# PCIE1_CORE_DBN_CFG_PCIE_CORE register map
Vendor: Texas Instruments
Registers are 32-bit, read-write, reset 0x0 unless marked. A register's access mark holds for its fields unless they carry their own. Offsets are as the file gives them; [hi:lo] are bit positions; {n}, {i} and the like mark numbered series; 'fields as' and 'values as' point back to an identical list.

## PCIE1_CORE_DBN_CFG_PCIE_CORE (part 7 of 7)
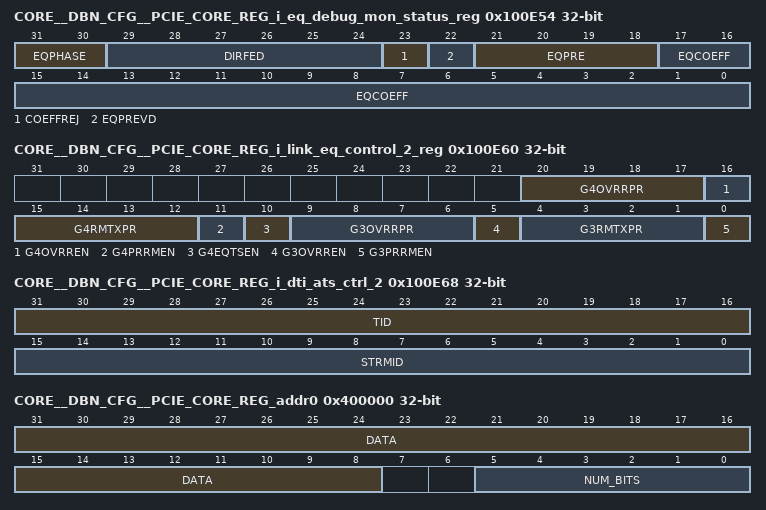
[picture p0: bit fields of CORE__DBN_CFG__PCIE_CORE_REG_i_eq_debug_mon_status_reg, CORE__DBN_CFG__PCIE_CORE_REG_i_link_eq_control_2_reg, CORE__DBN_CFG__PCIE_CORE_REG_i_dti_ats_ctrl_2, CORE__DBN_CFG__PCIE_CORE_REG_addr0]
0x100E54 CORE__DBN_CFG__PCIE_CORE_REG_i_eq_debug_mon_status_reg ro — All the Dynamic Equalization information is captured in this Register.This is implemented using a synchronous FIFO which stores all the captured events as sepereate 32 bit entries.The define den_db_EQ_DEBUG_FIFO_NUM_ENTRIES in defines.h controls the number of entries of the FIFO.Every read increments the read pointer and the client must store the data read.The FIFO can be cleared using the 'Clear all Capture bit in the EQ Debug Monitor Control Register.
  [31:30] EQPHASE — Equalization Phase during Capture 00 : Phase 0, 01 : Phase 1, 10 : Phase 2, 11 : Phase 3
  [29:24] DIRFED — EP Ph2/RC Ph3: Stores Direction Change Feedback or Preset feedback Transmitted to Remote Device. Bit-22, EQPREVD, indicates if this is a Preset feedback or Direction Change Feedback. EP Ph3/RC Ph2: Reserved
  [23] COEFFREJ — Phase0: Set to '1' if an unsupported preset is received in Phase0. Phase1: Set to '0' since no reject in phase1. EP Ph2/RC Ph3: Indicates Reject by the Remote end device. This bit indicates that the current Coefficient or Preset was rejected by the remote end device. EP Ph3/RC Ph2: Indicates that Controller Rejected the received settings to Remote Device in the TX TS1/TS2. This Reject indicates the current Coefficients or Preset received from Remote Device are rejected
  [22] EQPREVD — 1: Preset Valid, Indicates [21:18] is valid. Phase0: Set to '1' to indicate that the intial Local Preset is Valid. Phase1: Set to '1' to indicate that the advertised Remote Preset is Valid. EP Ph2/RC Ph3: Set to 1 if controller provide preset feedback and to 0 for coefficient feedback. EP Ph3/RC Ph2: Reflects the use preset bit received from the remote end.
  [21:18] EQPRE — Phase0: Stores Initial Local TX Preset received in Phase0. Phase1: Stores Initial Remote Preset advertised in Phase1. EP Ph2/RC Phase3: Stores Current Preset of the Remote Device. EP Ph3/RC Phase2: Stores Preset Received from Remote Device.
  [17:0] EQCOEFF — Phase0: Stores Initial Local TX Coefficients mapped from Initial Preset. Phase1: Stores Initial Remote Coefficients advertised in Phase1. [Cp, LF, FS] , EP Ph2/RC Phase3: Stores Current Coefficients of the Remote Device. EP Ph3/RC Phase2: Stores Coefficients Received from Remote Device.
0x100E5C CORE__DBN_CFG__PCIE_CORE_REG_i_axi_feature_reg reset 0x2 — This register is for the control of AXI Features
  [1] SLVERRCTRL — This bit if set to 1, AXI Slave masks the SLVERR response to be given in case of UR or CRS completion for configuration requests. If this bit is set to 0,UR and CRS completions from the link causes SLVERR at AXI.
0x100E60 CORE__DBN_CFG__PCIE_CORE_REG_i_link_eq_control_2_reg — This register implements fields to control and override Link Equalization.
  [20:17] G4OVRRPR — This is a debug register field. Can be used in both EP and RP Mode. When enabled using bit-16, this Tx Preset will be applied to the local Transmitter throughout Gen4 regardless of Gen4 Equalization.
  [16] G4OVRREN — This is a debug bit. Can be used in both EP and RP Mode. If enabled, the Controller locally applies the Gen4 Local Override Tx Preset to the Local Transmitter throughout Gen4. The Controller performs the Override Preset to Coefficient mapping and then drives on PIPE_TX_DEEMPHASIS signal on the PIPE Interface.
  [15:12] G4RMTXPR — Used only in EP Mode. If enabled, this Tx Preset will be transmitted in 8G EQ TS2s during Gen3 to Gen4 Speed Change negotiation. Also, If enabled, this Tx Preset will be transmitted in TS1s in the first iteration of Gen4 Equalization Phase2. Note: If the Remote end device advertised the same preset at start of Equalization Phase2, then this Preset will be skipped.
  [11] G4PRRMEN — Used only in EP Mode. This bit enables the Controller, to feedback a Tx Preset for the Remote end Transmitter in the first iteration of Link Equalization Phase2 at Gen4 speed. The Gen4 Tx Preset that is used for feedback is programmable in bits [15:12] of this register.
  [10] G4EQTSEN — Used only in EP Mode. During Gen3 to Gen4 Speed Change negotiation, this bit enables the Controller in EP Mode to transmit 8G EQ TS2 in Recovery.Rcvr.Cfg state instead of standard TS2 as defined in PCIe specification. The Tx Preset that will be used in the 8GT EQ TS2 is programmable in bits [15:12] of this register.
  [9:6] G3OVRRPR — This is a debug register field. Can be used in both EP and RP Mode. When enabled using bit-5, this Tx Preset will be applied to the local Transmitter throughout Gen3 regardless of Gen3 Equalization.
  [5] G3OVRREN — This is a debug bit. Can be used in both EP and RP Mode. If enabled, the Controller locally applies the Gen3 Local Override Tx Preset to the Local Transmitter throughout Gen3. The Controller performs the Override Preset to Coefficient mapping and then drives on PIPE_TX_DEEMPHASIS signal on the PIPE Interface.
  [4:1] G3RMTXPR — Used only in EP Mode. When enabled using bit-0, this Tx Preset will be transmitted in TS1s for the Remote end Transmitter in the first iteration of Gen3 Equalization Phase2. Reserved for RP Mode.
  [0] G3PRRMEN — Used only in EP Mode. This bit enables the Controller, to feedback a Tx Preset for the Remote end Transmitter in the first iteration of Link Equalization Phase2 at Gen3 speed. The Gen3 Tx Preset that is used for feedback is programmable in bits [4:1] of this register. Reserved for RP Mode.
0x100E64 CORE__DBN_CFG__PCIE_CORE_REG_i_core_feature_reg — This register is for the control of Core Features
  [1] APBCTRL — When set the Core will return SLVERR on the APB bus for Read or Writes to Configuration or Local Management registers
0x100E68 CORE__DBN_CFG__PCIE_CORE_REG_i_dti_ats_ctrl_2 — This register is for the control of DTI ATS Master
  [31:16] TID — This 16 bit value is used to drive the 16 bit TID_DTI_DN pin of the DTI Master
  [15:0] STRMID — This 16 bit value is used to filter [upper 16 bits of the SID is matched with this value] the DTI_ATS_INV_REQ and DTI_ATS_PAGE_RESP messages sent[broadcast] from the SMMU in case of multiple DTI Masters. This value used for the upper 16 bits of the SID in DTI_ATS_TRANS_REQ and DTI_ATS_PAGE_REQ
0x100E88 CORE__DBN_CFG__PCIE_CORE_REG_i_rx_invert_polarity_reg ro — This register shows the polarity inversion status of each lane
  [3:0] RIPR — shows the polarity inversion status of each lane
0x400000 CORE__DBN_CFG__PCIE_CORE_REG_addr0 access per field — Provides bits 31:8 of the PCIe address and the number of AXI address bits passed through
  [31:8] DATA rw — Bits [31:8] of PCIe Address Register for region N
  [5:0] NUM_BITS rw — Number_bits + 1 bits are passed through from AXI address to the PCIe address
0x400004 CORE__DBN_CFG__PCIE_CORE_REG_addr1 — Provides bits 63:32 of the PCIe address
  [31:0] DATA — Bits [63:32] of PCIe Address Register for region N
0x400008 CORE__DBN_CFG__PCIE_CORE_REG_desc0 — Provides bits 31:0 of the Outbound PCIe Descriptor
  [31:0] DATA — Lowest 32-bits of PCIe Descriptor Register for region N
0x40000C CORE__DBN_CFG__PCIE_CORE_REG_desc1 — Provides bits 63:32 of the PCIe Descriptor
  [31:0] DATA — Lower middle 32-bits of PCIe Descriptor Register for region N
0x400014 CORE__DBN_CFG__PCIE_CORE_REG_desc3 — Provides PASID Value and The present bit
  [22:0] DATA — {Execute Permission Supported, Privileged Mode Supported, PASID Value, PASID present bit}
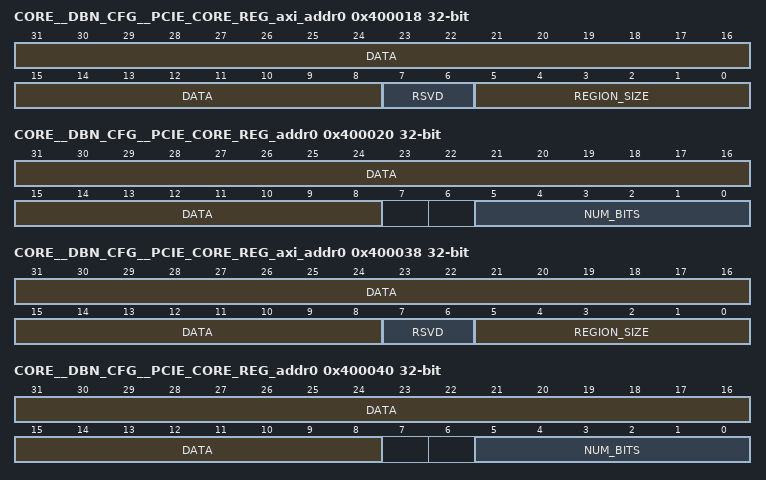
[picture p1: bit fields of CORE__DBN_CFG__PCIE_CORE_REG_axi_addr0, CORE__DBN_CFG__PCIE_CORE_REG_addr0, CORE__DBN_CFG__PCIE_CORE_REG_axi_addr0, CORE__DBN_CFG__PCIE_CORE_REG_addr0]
0x400018 CORE__DBN_CFG__PCIE_CORE_REG_axi_addr0 — holds the base address [31:8] of this region. Lower [5:0] is used for region size programmability
  [31:8] DATA — Bits [31:8] of Outbound AXI Region Base Address Register used to decode the region
  [7:6] RSVD — These needs to be forced to 0
  [5:0] REGION_SIZE — the value programmed in this field + 1 gives the region size
0x40001C CORE__DBN_CFG__PCIE_CORE_REG_axi_addr1 — holds the base address [63:32] of this region.
  [31:0] DATA — Bits [63:32] of AXI outbound Base Address Register used to decode the region
0x400020 CORE__DBN_CFG__PCIE_CORE_REG_addr0 access per field — Provides bits 31:8 of the PCIe address and the number of AXI address bits passed through
  fields as CORE__DBN_CFG__PCIE_CORE_REG_addr0
0x400024 CORE__DBN_CFG__PCIE_CORE_REG_addr1 — Provides bits 63:32 of the PCIe address
  [31:0] DATA — Bits [63:32] of PCIe Address Register for region N
0x400028 CORE__DBN_CFG__PCIE_CORE_REG_desc0 — Provides bits 31:0 of the Outbound PCIe Descriptor
  fields as CORE__DBN_CFG__PCIE_CORE_REG_desc0
0x40002C CORE__DBN_CFG__PCIE_CORE_REG_desc1 — Provides bits 63:32 of the PCIe Descriptor
  fields as CORE__DBN_CFG__PCIE_CORE_REG_desc1
0x400034 CORE__DBN_CFG__PCIE_CORE_REG_desc3 — Provides PASID Value and The present bit
  fields as CORE__DBN_CFG__PCIE_CORE_REG_desc3
0x400038 CORE__DBN_CFG__PCIE_CORE_REG_axi_addr0 — holds the base address [31:8] of this region. Lower [5:0] is used for region size programmability
  fields as CORE__DBN_CFG__PCIE_CORE_REG_axi_addr0
0x40003C CORE__DBN_CFG__PCIE_CORE_REG_axi_addr1 — holds the base address [63:32] of this region.
  fields as CORE__DBN_CFG__PCIE_CORE_REG_axi_addr1
0x400040 CORE__DBN_CFG__PCIE_CORE_REG_addr0 access per field — Provides bits 31:8 of the PCIe address and the number of AXI address bits passed through
  fields as CORE__DBN_CFG__PCIE_CORE_REG_addr0
0x400044 CORE__DBN_CFG__PCIE_CORE_REG_addr1 — Provides bits 63:32 of the PCIe address
  [31:0] DATA — Bits [63:32] of PCIe Address Register for region N
0x400048 CORE__DBN_CFG__PCIE_CORE_REG_desc0 — Provides bits 31:0 of the Outbound PCIe Descriptor
  fields as CORE__DBN_CFG__PCIE_CORE_REG_desc0
0x40004C CORE__DBN_CFG__PCIE_CORE_REG_desc1 — Provides bits 63:32 of the PCIe Descriptor
  fields as CORE__DBN_CFG__PCIE_CORE_REG_desc1
0x400054 CORE__DBN_CFG__PCIE_CORE_REG_desc3 — Provides PASID Value and The present bit
  fields as CORE__DBN_CFG__PCIE_CORE_REG_desc3
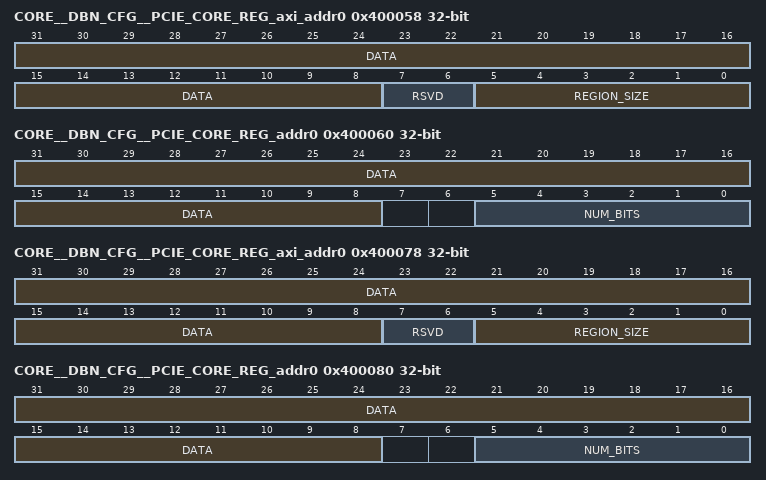
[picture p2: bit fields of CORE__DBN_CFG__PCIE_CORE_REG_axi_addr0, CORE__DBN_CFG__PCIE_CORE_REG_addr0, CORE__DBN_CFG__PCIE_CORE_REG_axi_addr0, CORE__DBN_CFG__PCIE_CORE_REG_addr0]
0x400058 CORE__DBN_CFG__PCIE_CORE_REG_axi_addr0 — holds the base address [31:8] of this region. Lower [5:0] is used for region size programmability
  fields as CORE__DBN_CFG__PCIE_CORE_REG_axi_addr0
0x40005C CORE__DBN_CFG__PCIE_CORE_REG_axi_addr1 — holds the base address [63:32] of this region.
  fields as CORE__DBN_CFG__PCIE_CORE_REG_axi_addr1
0x400060 CORE__DBN_CFG__PCIE_CORE_REG_addr0 access per field — Provides bits 31:8 of the PCIe address and the number of AXI address bits passed through
  fields as CORE__DBN_CFG__PCIE_CORE_REG_addr0
0x400064 CORE__DBN_CFG__PCIE_CORE_REG_addr1 — Provides bits 63:32 of the PCIe address
  [31:0] DATA — Bits [63:32] of PCIe Address Register for region N
0x400068 CORE__DBN_CFG__PCIE_CORE_REG_desc0 — Provides bits 31:0 of the Outbound PCIe Descriptor
  fields as CORE__DBN_CFG__PCIE_CORE_REG_desc0
0x40006C CORE__DBN_CFG__PCIE_CORE_REG_desc1 — Provides bits 63:32 of the PCIe Descriptor
  fields as CORE__DBN_CFG__PCIE_CORE_REG_desc1
0x400074 CORE__DBN_CFG__PCIE_CORE_REG_desc3 — Provides PASID Value and The present bit
  fields as CORE__DBN_CFG__PCIE_CORE_REG_desc3
0x400078 CORE__DBN_CFG__PCIE_CORE_REG_axi_addr0 — holds the base address [31:8] of this region. Lower [5:0] is used for region size programmability
  fields as CORE__DBN_CFG__PCIE_CORE_REG_axi_addr0
0x40007C CORE__DBN_CFG__PCIE_CORE_REG_axi_addr1 — holds the base address [63:32] of this region.
  fields as CORE__DBN_CFG__PCIE_CORE_REG_axi_addr1
0x400080 CORE__DBN_CFG__PCIE_CORE_REG_addr0 access per field — Provides bits 31:8 of the PCIe address and the number of AXI address bits passed through
  fields as CORE__DBN_CFG__PCIE_CORE_REG_addr0
0x400084 CORE__DBN_CFG__PCIE_CORE_REG_addr1 — Provides bits 63:32 of the PCIe address
  [31:0] DATA — Bits [63:32] of PCIe Address Register for region N
0x400088 CORE__DBN_CFG__PCIE_CORE_REG_desc0 — Provides bits 31:0 of the Outbound PCIe Descriptor
  fields as CORE__DBN_CFG__PCIE_CORE_REG_desc0
0x40008C CORE__DBN_CFG__PCIE_CORE_REG_desc1 — Provides bits 63:32 of the PCIe Descriptor
  fields as CORE__DBN_CFG__PCIE_CORE_REG_desc1
0x400094 CORE__DBN_CFG__PCIE_CORE_REG_desc3 — Provides PASID Value and The present bit
  fields as CORE__DBN_CFG__PCIE_CORE_REG_desc3
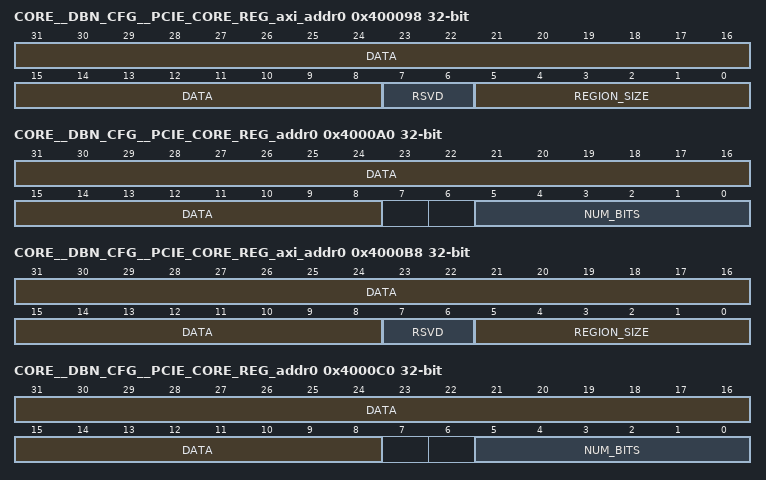
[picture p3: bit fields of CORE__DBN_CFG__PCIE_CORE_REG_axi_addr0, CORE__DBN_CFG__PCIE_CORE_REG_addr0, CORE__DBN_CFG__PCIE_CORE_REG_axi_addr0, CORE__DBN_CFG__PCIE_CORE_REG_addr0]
0x400098 CORE__DBN_CFG__PCIE_CORE_REG_axi_addr0 — holds the base address [31:8] of this region. Lower [5:0] is used for region size programmability
  fields as CORE__DBN_CFG__PCIE_CORE_REG_axi_addr0
0x40009C CORE__DBN_CFG__PCIE_CORE_REG_axi_addr1 — holds the base address [63:32] of this region.
  fields as CORE__DBN_CFG__PCIE_CORE_REG_axi_addr1
0x4000A0 CORE__DBN_CFG__PCIE_CORE_REG_addr0 access per field — Provides bits 31:8 of the PCIe address and the number of AXI address bits passed through
  fields as CORE__DBN_CFG__PCIE_CORE_REG_addr0
0x4000A4 CORE__DBN_CFG__PCIE_CORE_REG_addr1 — Provides bits 63:32 of the PCIe address
  [31:0] DATA — Bits [63:32] of PCIe Address Register for region N
0x4000A8 CORE__DBN_CFG__PCIE_CORE_REG_desc0 — Provides bits 31:0 of the Outbound PCIe Descriptor
  fields as CORE__DBN_CFG__PCIE_CORE_REG_desc0
0x4000AC CORE__DBN_CFG__PCIE_CORE_REG_desc1 — Provides bits 63:32 of the PCIe Descriptor
  fields as CORE__DBN_CFG__PCIE_CORE_REG_desc1
0x4000B4 CORE__DBN_CFG__PCIE_CORE_REG_desc3 — Provides PASID Value and The present bit
  fields as CORE__DBN_CFG__PCIE_CORE_REG_desc3
0x4000B8 CORE__DBN_CFG__PCIE_CORE_REG_axi_addr0 — holds the base address [31:8] of this region. Lower [5:0] is used for region size programmability
  fields as CORE__DBN_CFG__PCIE_CORE_REG_axi_addr0
0x4000BC CORE__DBN_CFG__PCIE_CORE_REG_axi_addr1 — holds the base address [63:32] of this region.
  fields as CORE__DBN_CFG__PCIE_CORE_REG_axi_addr1
0x4000C0 CORE__DBN_CFG__PCIE_CORE_REG_addr0 access per field — Provides bits 31:8 of the PCIe address and the number of AXI address bits passed through
  fields as CORE__DBN_CFG__PCIE_CORE_REG_addr0
0x4000C4 CORE__DBN_CFG__PCIE_CORE_REG_addr1 — Provides bits 63:32 of the PCIe address
  [31:0] DATA — Bits [63:32] of PCIe Address Register for region N
0x4000C8 CORE__DBN_CFG__PCIE_CORE_REG_desc0 — Provides bits 31:0 of the Outbound PCIe Descriptor
  fields as CORE__DBN_CFG__PCIE_CORE_REG_desc0
0x4000CC CORE__DBN_CFG__PCIE_CORE_REG_desc1 — Provides bits 63:32 of the PCIe Descriptor
  fields as CORE__DBN_CFG__PCIE_CORE_REG_desc1
0x4000D4 CORE__DBN_CFG__PCIE_CORE_REG_desc3 — Provides PASID Value and The present bit
  fields as CORE__DBN_CFG__PCIE_CORE_REG_desc3
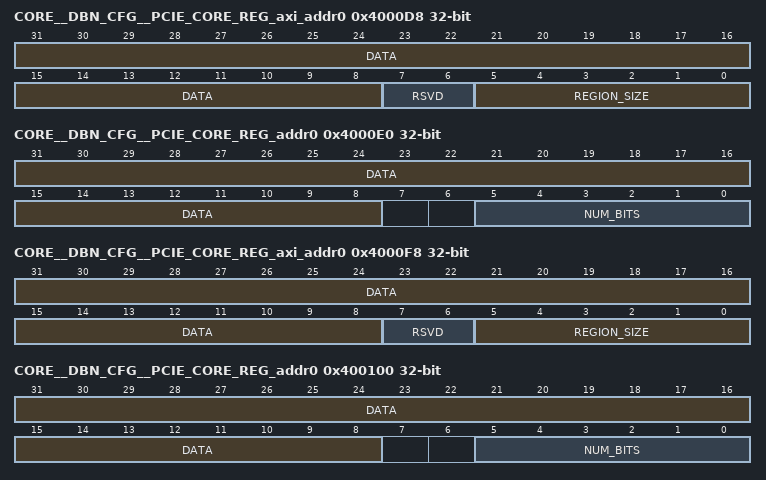
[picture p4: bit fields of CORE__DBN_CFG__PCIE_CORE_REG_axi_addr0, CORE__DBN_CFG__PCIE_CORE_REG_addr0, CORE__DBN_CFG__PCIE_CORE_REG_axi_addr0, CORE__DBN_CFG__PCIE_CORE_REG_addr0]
0x4000D8 CORE__DBN_CFG__PCIE_CORE_REG_axi_addr0 — holds the base address [31:8] of this region. Lower [5:0] is used for region size programmability
  fields as CORE__DBN_CFG__PCIE_CORE_REG_axi_addr0
0x4000DC CORE__DBN_CFG__PCIE_CORE_REG_axi_addr1 — holds the base address [63:32] of this region.
  fields as CORE__DBN_CFG__PCIE_CORE_REG_axi_addr1
0x4000E0 CORE__DBN_CFG__PCIE_CORE_REG_addr0 access per field — Provides bits 31:8 of the PCIe address and the number of AXI address bits passed through
  fields as CORE__DBN_CFG__PCIE_CORE_REG_addr0
0x4000E4 CORE__DBN_CFG__PCIE_CORE_REG_addr1 — Provides bits 63:32 of the PCIe address
  [31:0] DATA — Bits [63:32] of PCIe Address Register for region N
0x4000E8 CORE__DBN_CFG__PCIE_CORE_REG_desc0 — Provides bits 31:0 of the Outbound PCIe Descriptor
  fields as CORE__DBN_CFG__PCIE_CORE_REG_desc0
0x4000EC CORE__DBN_CFG__PCIE_CORE_REG_desc1 — Provides bits 63:32 of the PCIe Descriptor
  fields as CORE__DBN_CFG__PCIE_CORE_REG_desc1
0x4000F4 CORE__DBN_CFG__PCIE_CORE_REG_desc3 — Provides PASID Value and The present bit
  fields as CORE__DBN_CFG__PCIE_CORE_REG_desc3
0x4000F8 CORE__DBN_CFG__PCIE_CORE_REG_axi_addr0 — holds the base address [31:8] of this region. Lower [5:0] is used for region size programmability
  fields as CORE__DBN_CFG__PCIE_CORE_REG_axi_addr0
0x4000FC CORE__DBN_CFG__PCIE_CORE_REG_axi_addr1 — holds the base address [63:32] of this region.
  fields as CORE__DBN_CFG__PCIE_CORE_REG_axi_addr1
0x400100 CORE__DBN_CFG__PCIE_CORE_REG_addr0 access per field — Provides bits 31:8 of the PCIe address and the number of AXI address bits passed through
  fields as CORE__DBN_CFG__PCIE_CORE_REG_addr0
0x400104 CORE__DBN_CFG__PCIE_CORE_REG_addr1 — Provides bits 63:32 of the PCIe address
  [31:0] DATA — Bits [63:32] of PCIe Address Register for region N
0x400108 CORE__DBN_CFG__PCIE_CORE_REG_desc0 — Provides bits 31:0 of the Outbound PCIe Descriptor
  fields as CORE__DBN_CFG__PCIE_CORE_REG_desc0
0x40010C CORE__DBN_CFG__PCIE_CORE_REG_desc1 — Provides bits 63:32 of the PCIe Descriptor
  fields as CORE__DBN_CFG__PCIE_CORE_REG_desc1
0x400114 CORE__DBN_CFG__PCIE_CORE_REG_desc3 — Provides PASID Value and The present bit
  fields as CORE__DBN_CFG__PCIE_CORE_REG_desc3
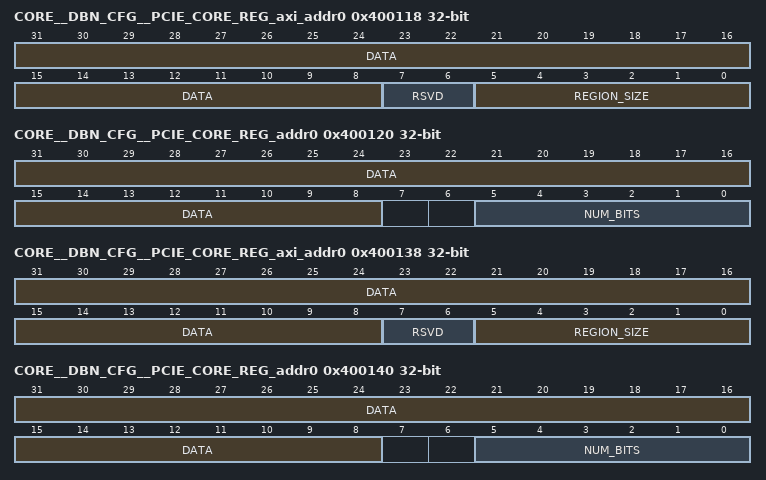
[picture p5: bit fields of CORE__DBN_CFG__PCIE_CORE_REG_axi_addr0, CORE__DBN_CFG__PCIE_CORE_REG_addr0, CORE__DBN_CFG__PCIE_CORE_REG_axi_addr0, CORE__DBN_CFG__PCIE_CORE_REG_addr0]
0x400118 CORE__DBN_CFG__PCIE_CORE_REG_axi_addr0 — holds the base address [31:8] of this region. Lower [5:0] is used for region size programmability
  fields as CORE__DBN_CFG__PCIE_CORE_REG_axi_addr0
0x40011C CORE__DBN_CFG__PCIE_CORE_REG_axi_addr1 — holds the base address [63:32] of this region.
  fields as CORE__DBN_CFG__PCIE_CORE_REG_axi_addr1
0x400120 CORE__DBN_CFG__PCIE_CORE_REG_addr0 access per field — Provides bits 31:8 of the PCIe address and the number of AXI address bits passed through
  fields as CORE__DBN_CFG__PCIE_CORE_REG_addr0
0x400124 CORE__DBN_CFG__PCIE_CORE_REG_addr1 — Provides bits 63:32 of the PCIe address
  [31:0] DATA — Bits [63:32] of PCIe Address Register for region N
0x400128 CORE__DBN_CFG__PCIE_CORE_REG_desc0 — Provides bits 31:0 of the Outbound PCIe Descriptor
  fields as CORE__DBN_CFG__PCIE_CORE_REG_desc0
0x40012C CORE__DBN_CFG__PCIE_CORE_REG_desc1 — Provides bits 63:32 of the PCIe Descriptor
  fields as CORE__DBN_CFG__PCIE_CORE_REG_desc1
0x400134 CORE__DBN_CFG__PCIE_CORE_REG_desc3 — Provides PASID Value and The present bit
  fields as CORE__DBN_CFG__PCIE_CORE_REG_desc3
0x400138 CORE__DBN_CFG__PCIE_CORE_REG_axi_addr0 — holds the base address [31:8] of this region. Lower [5:0] is used for region size programmability
  fields as CORE__DBN_CFG__PCIE_CORE_REG_axi_addr0
0x40013C CORE__DBN_CFG__PCIE_CORE_REG_axi_addr1 — holds the base address [63:32] of this region.
  fields as CORE__DBN_CFG__PCIE_CORE_REG_axi_addr1
0x400140 CORE__DBN_CFG__PCIE_CORE_REG_addr0 access per field — Provides bits 31:8 of the PCIe address and the number of AXI address bits passed through
  fields as CORE__DBN_CFG__PCIE_CORE_REG_addr0
0x400144 CORE__DBN_CFG__PCIE_CORE_REG_addr1 — Provides bits 63:32 of the PCIe address
  [31:0] DATA — Bits [63:32] of PCIe Address Register for region N
0x400148 CORE__DBN_CFG__PCIE_CORE_REG_desc0 — Provides bits 31:0 of the Outbound PCIe Descriptor
  fields as CORE__DBN_CFG__PCIE_CORE_REG_desc0
0x40014C CORE__DBN_CFG__PCIE_CORE_REG_desc1 — Provides bits 63:32 of the PCIe Descriptor
  fields as CORE__DBN_CFG__PCIE_CORE_REG_desc1
0x400154 CORE__DBN_CFG__PCIE_CORE_REG_desc3 — Provides PASID Value and The present bit
  fields as CORE__DBN_CFG__PCIE_CORE_REG_desc3
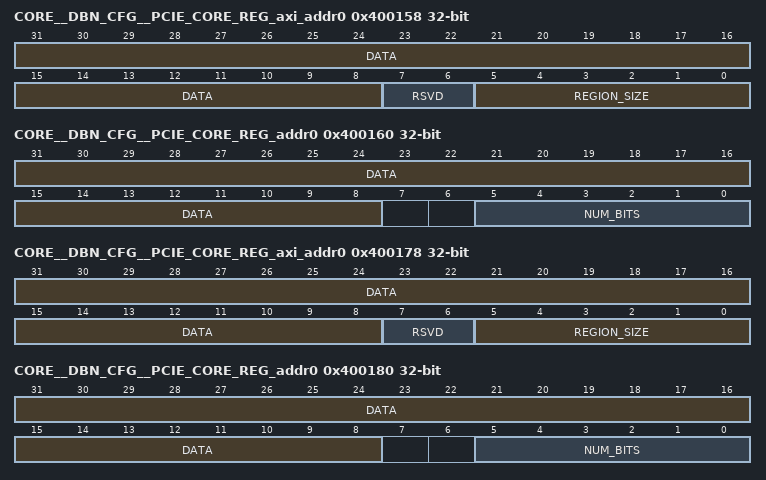
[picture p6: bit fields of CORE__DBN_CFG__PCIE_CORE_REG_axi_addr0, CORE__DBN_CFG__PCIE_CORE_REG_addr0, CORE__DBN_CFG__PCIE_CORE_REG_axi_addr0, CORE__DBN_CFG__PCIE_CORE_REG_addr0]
0x400158 CORE__DBN_CFG__PCIE_CORE_REG_axi_addr0 — holds the base address [31:8] of this region. Lower [5:0] is used for region size programmability
  fields as CORE__DBN_CFG__PCIE_CORE_REG_axi_addr0
0x40015C CORE__DBN_CFG__PCIE_CORE_REG_axi_addr1 — holds the base address [63:32] of this region.
  fields as CORE__DBN_CFG__PCIE_CORE_REG_axi_addr1
0x400160 CORE__DBN_CFG__PCIE_CORE_REG_addr0 access per field — Provides bits 31:8 of the PCIe address and the number of AXI address bits passed through
  fields as CORE__DBN_CFG__PCIE_CORE_REG_addr0
0x400164 CORE__DBN_CFG__PCIE_CORE_REG_addr1 — Provides bits 63:32 of the PCIe address
  [31:0] DATA — Bits [63:32] of PCIe Address Register for region N
0x400168 CORE__DBN_CFG__PCIE_CORE_REG_desc0 — Provides bits 31:0 of the Outbound PCIe Descriptor
  fields as CORE__DBN_CFG__PCIE_CORE_REG_desc0
0x40016C CORE__DBN_CFG__PCIE_CORE_REG_desc1 — Provides bits 63:32 of the PCIe Descriptor
  fields as CORE__DBN_CFG__PCIE_CORE_REG_desc1
0x400174 CORE__DBN_CFG__PCIE_CORE_REG_desc3 — Provides PASID Value and The present bit
  fields as CORE__DBN_CFG__PCIE_CORE_REG_desc3
0x400178 CORE__DBN_CFG__PCIE_CORE_REG_axi_addr0 — holds the base address [31:8] of this region. Lower [5:0] is used for region size programmability
  fields as CORE__DBN_CFG__PCIE_CORE_REG_axi_addr0
0x40017C CORE__DBN_CFG__PCIE_CORE_REG_axi_addr1 — holds the base address [63:32] of this region.
  fields as CORE__DBN_CFG__PCIE_CORE_REG_axi_addr1
0x400180 CORE__DBN_CFG__PCIE_CORE_REG_addr0 access per field — Provides bits 31:8 of the PCIe address and the number of AXI address bits passed through
  fields as CORE__DBN_CFG__PCIE_CORE_REG_addr0
0x400184 CORE__DBN_CFG__PCIE_CORE_REG_addr1 — Provides bits 63:32 of the PCIe address
  [31:0] DATA — Bits [63:32] of PCIe Address Register for region N
0x400188 CORE__DBN_CFG__PCIE_CORE_REG_desc0 — Provides bits 31:0 of the Outbound PCIe Descriptor
  fields as CORE__DBN_CFG__PCIE_CORE_REG_desc0
0x40018C CORE__DBN_CFG__PCIE_CORE_REG_desc1 — Provides bits 63:32 of the PCIe Descriptor
  fields as CORE__DBN_CFG__PCIE_CORE_REG_desc1
0x400194 CORE__DBN_CFG__PCIE_CORE_REG_desc3 — Provides PASID Value and The present bit
  fields as CORE__DBN_CFG__PCIE_CORE_REG_desc3
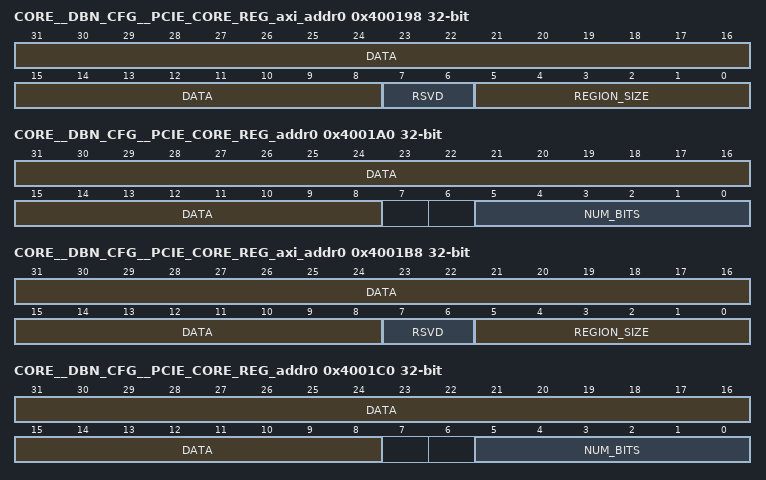
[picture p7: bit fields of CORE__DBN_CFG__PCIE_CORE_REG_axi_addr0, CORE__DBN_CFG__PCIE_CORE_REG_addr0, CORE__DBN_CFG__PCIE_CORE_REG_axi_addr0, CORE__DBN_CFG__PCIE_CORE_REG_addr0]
0x400198 CORE__DBN_CFG__PCIE_CORE_REG_axi_addr0 — holds the base address [31:8] of this region. Lower [5:0] is used for region size programmability
  fields as CORE__DBN_CFG__PCIE_CORE_REG_axi_addr0
0x40019C CORE__DBN_CFG__PCIE_CORE_REG_axi_addr1 — holds the base address [63:32] of this region.
  fields as CORE__DBN_CFG__PCIE_CORE_REG_axi_addr1
0x4001A0 CORE__DBN_CFG__PCIE_CORE_REG_addr0 access per field — Provides bits 31:8 of the PCIe address and the number of AXI address bits passed through
  fields as CORE__DBN_CFG__PCIE_CORE_REG_addr0
0x4001A4 CORE__DBN_CFG__PCIE_CORE_REG_addr1 — Provides bits 63:32 of the PCIe address
  [31:0] DATA — Bits [63:32] of PCIe Address Register for region N
0x4001A8 CORE__DBN_CFG__PCIE_CORE_REG_desc0 — Provides bits 31:0 of the Outbound PCIe Descriptor
  fields as CORE__DBN_CFG__PCIE_CORE_REG_desc0
0x4001AC CORE__DBN_CFG__PCIE_CORE_REG_desc1 — Provides bits 63:32 of the PCIe Descriptor
  fields as CORE__DBN_CFG__PCIE_CORE_REG_desc1
0x4001B4 CORE__DBN_CFG__PCIE_CORE_REG_desc3 — Provides PASID Value and The present bit
  fields as CORE__DBN_CFG__PCIE_CORE_REG_desc3
0x4001B8 CORE__DBN_CFG__PCIE_CORE_REG_axi_addr0 — holds the base address [31:8] of this region. Lower [5:0] is used for region size programmability
  fields as CORE__DBN_CFG__PCIE_CORE_REG_axi_addr0
0x4001BC CORE__DBN_CFG__PCIE_CORE_REG_axi_addr1 — holds the base address [63:32] of this region.
  fields as CORE__DBN_CFG__PCIE_CORE_REG_axi_addr1
0x4001C0 CORE__DBN_CFG__PCIE_CORE_REG_addr0 access per field — Provides bits 31:8 of the PCIe address and the number of AXI address bits passed through
  fields as CORE__DBN_CFG__PCIE_CORE_REG_addr0
0x4001C4 CORE__DBN_CFG__PCIE_CORE_REG_addr1 — Provides bits 63:32 of the PCIe address
  [31:0] DATA — Bits [63:32] of PCIe Address Register for region N
0x4001C8 CORE__DBN_CFG__PCIE_CORE_REG_desc0 — Provides bits 31:0 of the Outbound PCIe Descriptor
  fields as CORE__DBN_CFG__PCIE_CORE_REG_desc0
0x4001CC CORE__DBN_CFG__PCIE_CORE_REG_desc1 — Provides bits 63:32 of the PCIe Descriptor
  fields as CORE__DBN_CFG__PCIE_CORE_REG_desc1
0x4001D4 CORE__DBN_CFG__PCIE_CORE_REG_desc3 — Provides PASID Value and The present bit
  fields as CORE__DBN_CFG__PCIE_CORE_REG_desc3
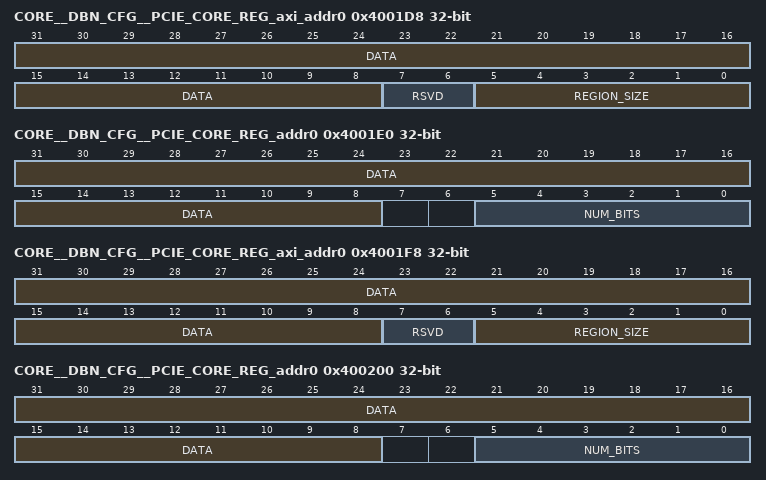
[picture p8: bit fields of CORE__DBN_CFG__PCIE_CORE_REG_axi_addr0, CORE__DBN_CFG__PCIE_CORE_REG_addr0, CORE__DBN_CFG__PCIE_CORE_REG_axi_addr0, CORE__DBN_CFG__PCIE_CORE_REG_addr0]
0x4001D8 CORE__DBN_CFG__PCIE_CORE_REG_axi_addr0 — holds the base address [31:8] of this region. Lower [5:0] is used for region size programmability
  fields as CORE__DBN_CFG__PCIE_CORE_REG_axi_addr0
0x4001DC CORE__DBN_CFG__PCIE_CORE_REG_axi_addr1 — holds the base address [63:32] of this region.
  fields as CORE__DBN_CFG__PCIE_CORE_REG_axi_addr1
0x4001E0 CORE__DBN_CFG__PCIE_CORE_REG_addr0 access per field — Provides bits 31:8 of the PCIe address and the number of AXI address bits passed through
  fields as CORE__DBN_CFG__PCIE_CORE_REG_addr0
0x4001E4 CORE__DBN_CFG__PCIE_CORE_REG_addr1 — Provides bits 63:32 of the PCIe address
  [31:0] DATA — Bits [63:32] of PCIe Address Register for region N
0x4001E8 CORE__DBN_CFG__PCIE_CORE_REG_desc0 — Provides bits 31:0 of the Outbound PCIe Descriptor
  fields as CORE__DBN_CFG__PCIE_CORE_REG_desc0
0x4001EC CORE__DBN_CFG__PCIE_CORE_REG_desc1 — Provides bits 63:32 of the PCIe Descriptor
  fields as CORE__DBN_CFG__PCIE_CORE_REG_desc1
0x4001F4 CORE__DBN_CFG__PCIE_CORE_REG_desc3 — Provides PASID Value and The present bit
  fields as CORE__DBN_CFG__PCIE_CORE_REG_desc3
0x4001F8 CORE__DBN_CFG__PCIE_CORE_REG_axi_addr0 — holds the base address [31:8] of this region. Lower [5:0] is used for region size programmability
  fields as CORE__DBN_CFG__PCIE_CORE_REG_axi_addr0
0x4001FC CORE__DBN_CFG__PCIE_CORE_REG_axi_addr1 — holds the base address [63:32] of this region.
  fields as CORE__DBN_CFG__PCIE_CORE_REG_axi_addr1
0x400200 CORE__DBN_CFG__PCIE_CORE_REG_addr0 access per field — Provides bits 31:8 of the PCIe address and the number of AXI address bits passed through
  fields as CORE__DBN_CFG__PCIE_CORE_REG_addr0
0x400204 CORE__DBN_CFG__PCIE_CORE_REG_addr1 — Provides bits 63:32 of the PCIe address
  [31:0] DATA — Bits [63:32] of PCIe Address Register for region N
0x400208 CORE__DBN_CFG__PCIE_CORE_REG_desc0 — Provides bits 31:0 of the Outbound PCIe Descriptor
  fields as CORE__DBN_CFG__PCIE_CORE_REG_desc0
0x40020C CORE__DBN_CFG__PCIE_CORE_REG_desc1 — Provides bits 63:32 of the PCIe Descriptor
  fields as CORE__DBN_CFG__PCIE_CORE_REG_desc1
0x400214 CORE__DBN_CFG__PCIE_CORE_REG_desc3 — Provides PASID Value and The present bit
  fields as CORE__DBN_CFG__PCIE_CORE_REG_desc3
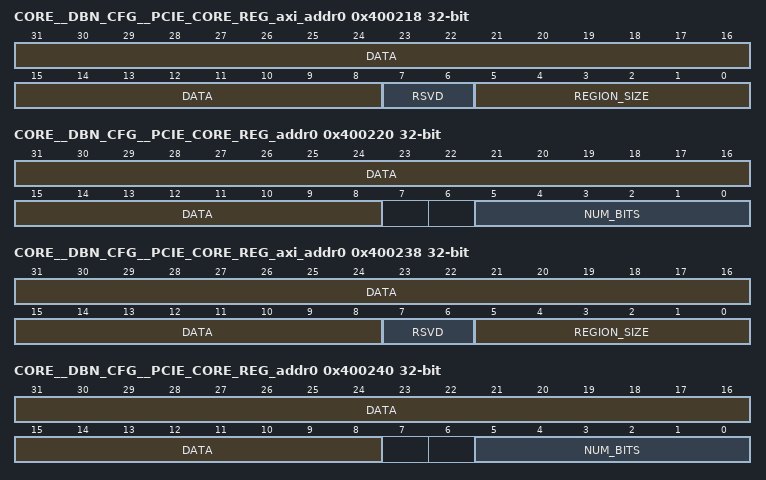
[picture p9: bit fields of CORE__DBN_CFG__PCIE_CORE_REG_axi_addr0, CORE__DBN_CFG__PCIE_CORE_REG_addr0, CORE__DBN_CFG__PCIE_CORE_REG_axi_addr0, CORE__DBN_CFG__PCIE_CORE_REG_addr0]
0x400218 CORE__DBN_CFG__PCIE_CORE_REG_axi_addr0 — holds the base address [31:8] of this region. Lower [5:0] is used for region size programmability
  fields as CORE__DBN_CFG__PCIE_CORE_REG_axi_addr0
0x40021C CORE__DBN_CFG__PCIE_CORE_REG_axi_addr1 — holds the base address [63:32] of this region.
  fields as CORE__DBN_CFG__PCIE_CORE_REG_axi_addr1
0x400220 CORE__DBN_CFG__PCIE_CORE_REG_addr0 access per field — Provides bits 31:8 of the PCIe address and the number of AXI address bits passed through
  fields as CORE__DBN_CFG__PCIE_CORE_REG_addr0
0x400224 CORE__DBN_CFG__PCIE_CORE_REG_addr1 — Provides bits 63:32 of the PCIe address
  [31:0] DATA — Bits [63:32] of PCIe Address Register for region N
0x400228 CORE__DBN_CFG__PCIE_CORE_REG_desc0 — Provides bits 31:0 of the Outbound PCIe Descriptor
  fields as CORE__DBN_CFG__PCIE_CORE_REG_desc0
0x40022C CORE__DBN_CFG__PCIE_CORE_REG_desc1 — Provides bits 63:32 of the PCIe Descriptor
  fields as CORE__DBN_CFG__PCIE_CORE_REG_desc1
0x400234 CORE__DBN_CFG__PCIE_CORE_REG_desc3 — Provides PASID Value and The present bit
  fields as CORE__DBN_CFG__PCIE_CORE_REG_desc3
0x400238 CORE__DBN_CFG__PCIE_CORE_REG_axi_addr0 — holds the base address [31:8] of this region. Lower [5:0] is used for region size programmability
  fields as CORE__DBN_CFG__PCIE_CORE_REG_axi_addr0
0x40023C CORE__DBN_CFG__PCIE_CORE_REG_axi_addr1 — holds the base address [63:32] of this region.
  fields as CORE__DBN_CFG__PCIE_CORE_REG_axi_addr1
0x400240 CORE__DBN_CFG__PCIE_CORE_REG_addr0 access per field — Provides bits 31:8 of the PCIe address and the number of AXI address bits passed through
  fields as CORE__DBN_CFG__PCIE_CORE_REG_addr0
0x400244 CORE__DBN_CFG__PCIE_CORE_REG_addr1 — Provides bits 63:32 of the PCIe address
  [31:0] DATA — Bits [63:32] of PCIe Address Register for region N
0x400248 CORE__DBN_CFG__PCIE_CORE_REG_desc0 — Provides bits 31:0 of the Outbound PCIe Descriptor
  fields as CORE__DBN_CFG__PCIE_CORE_REG_desc0
0x40024C CORE__DBN_CFG__PCIE_CORE_REG_desc1 — Provides bits 63:32 of the PCIe Descriptor
  fields as CORE__DBN_CFG__PCIE_CORE_REG_desc1
0x400254 CORE__DBN_CFG__PCIE_CORE_REG_desc3 — Provides PASID Value and The present bit
  fields as CORE__DBN_CFG__PCIE_CORE_REG_desc3
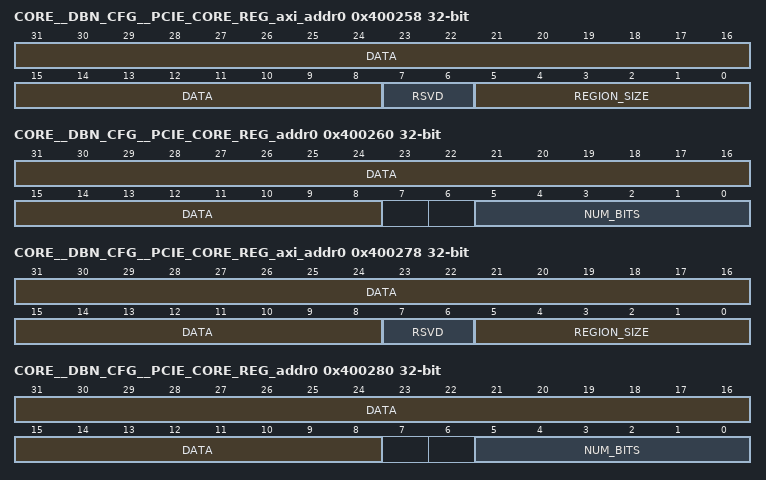
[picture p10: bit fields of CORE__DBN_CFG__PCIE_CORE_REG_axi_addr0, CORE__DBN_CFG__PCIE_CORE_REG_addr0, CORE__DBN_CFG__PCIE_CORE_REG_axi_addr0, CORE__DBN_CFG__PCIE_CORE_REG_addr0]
0x400258 CORE__DBN_CFG__PCIE_CORE_REG_axi_addr0 — holds the base address [31:8] of this region. Lower [5:0] is used for region size programmability
  fields as CORE__DBN_CFG__PCIE_CORE_REG_axi_addr0
0x40025C CORE__DBN_CFG__PCIE_CORE_REG_axi_addr1 — holds the base address [63:32] of this region.
  fields as CORE__DBN_CFG__PCIE_CORE_REG_axi_addr1
0x400260 CORE__DBN_CFG__PCIE_CORE_REG_addr0 access per field — Provides bits 31:8 of the PCIe address and the number of AXI address bits passed through
  fields as CORE__DBN_CFG__PCIE_CORE_REG_addr0
0x400264 CORE__DBN_CFG__PCIE_CORE_REG_addr1 — Provides bits 63:32 of the PCIe address
  [31:0] DATA — Bits [63:32] of PCIe Address Register for region N
0x400268 CORE__DBN_CFG__PCIE_CORE_REG_desc0 — Provides bits 31:0 of the Outbound PCIe Descriptor
  fields as CORE__DBN_CFG__PCIE_CORE_REG_desc0
0x40026C CORE__DBN_CFG__PCIE_CORE_REG_desc1 — Provides bits 63:32 of the PCIe Descriptor
  fields as CORE__DBN_CFG__PCIE_CORE_REG_desc1
0x400274 CORE__DBN_CFG__PCIE_CORE_REG_desc3 — Provides PASID Value and The present bit
  fields as CORE__DBN_CFG__PCIE_CORE_REG_desc3
0x400278 CORE__DBN_CFG__PCIE_CORE_REG_axi_addr0 — holds the base address [31:8] of this region. Lower [5:0] is used for region size programmability
  fields as CORE__DBN_CFG__PCIE_CORE_REG_axi_addr0
0x40027C CORE__DBN_CFG__PCIE_CORE_REG_axi_addr1 — holds the base address [63:32] of this region.
  fields as CORE__DBN_CFG__PCIE_CORE_REG_axi_addr1
0x400280 CORE__DBN_CFG__PCIE_CORE_REG_addr0 access per field — Provides bits 31:8 of the PCIe address and the number of AXI address bits passed through
  fields as CORE__DBN_CFG__PCIE_CORE_REG_addr0
0x400284 CORE__DBN_CFG__PCIE_CORE_REG_addr1 — Provides bits 63:32 of the PCIe address
  [31:0] DATA — Bits [63:32] of PCIe Address Register for region N
0x400288 CORE__DBN_CFG__PCIE_CORE_REG_desc0 — Provides bits 31:0 of the Outbound PCIe Descriptor
  fields as CORE__DBN_CFG__PCIE_CORE_REG_desc0
0x40028C CORE__DBN_CFG__PCIE_CORE_REG_desc1 — Provides bits 63:32 of the PCIe Descriptor
  fields as CORE__DBN_CFG__PCIE_CORE_REG_desc1
0x400294 CORE__DBN_CFG__PCIE_CORE_REG_desc3 — Provides PASID Value and The present bit
  fields as CORE__DBN_CFG__PCIE_CORE_REG_desc3
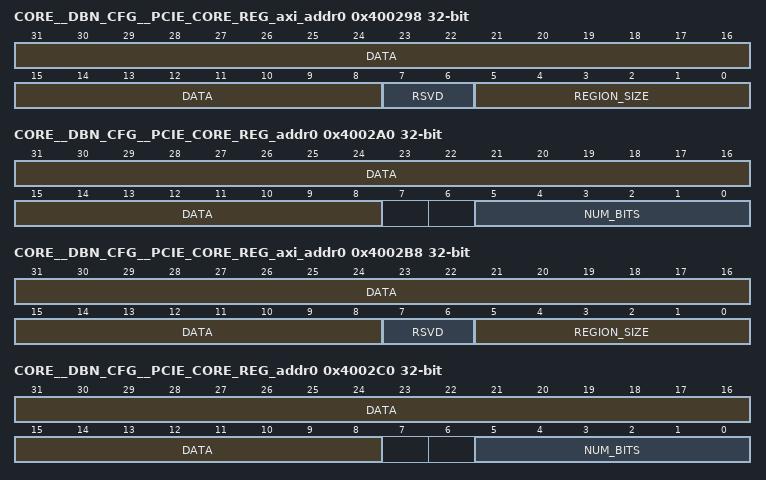
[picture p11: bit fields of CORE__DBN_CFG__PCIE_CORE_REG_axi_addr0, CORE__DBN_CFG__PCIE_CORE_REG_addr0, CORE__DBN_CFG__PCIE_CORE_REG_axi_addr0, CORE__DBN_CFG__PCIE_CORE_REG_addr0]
0x400298 CORE__DBN_CFG__PCIE_CORE_REG_axi_addr0 — holds the base address [31:8] of this region. Lower [5:0] is used for region size programmability
  fields as CORE__DBN_CFG__PCIE_CORE_REG_axi_addr0
0x40029C CORE__DBN_CFG__PCIE_CORE_REG_axi_addr1 — holds the base address [63:32] of this region.
  fields as CORE__DBN_CFG__PCIE_CORE_REG_axi_addr1
0x4002A0 CORE__DBN_CFG__PCIE_CORE_REG_addr0 access per field — Provides bits 31:8 of the PCIe address and the number of AXI address bits passed through
  fields as CORE__DBN_CFG__PCIE_CORE_REG_addr0
0x4002A4 CORE__DBN_CFG__PCIE_CORE_REG_addr1 — Provides bits 63:32 of the PCIe address
  [31:0] DATA — Bits [63:32] of PCIe Address Register for region N
0x4002A8 CORE__DBN_CFG__PCIE_CORE_REG_desc0 — Provides bits 31:0 of the Outbound PCIe Descriptor
  fields as CORE__DBN_CFG__PCIE_CORE_REG_desc0
0x4002AC CORE__DBN_CFG__PCIE_CORE_REG_desc1 — Provides bits 63:32 of the PCIe Descriptor
  fields as CORE__DBN_CFG__PCIE_CORE_REG_desc1
0x4002B4 CORE__DBN_CFG__PCIE_CORE_REG_desc3 — Provides PASID Value and The present bit
  fields as CORE__DBN_CFG__PCIE_CORE_REG_desc3
0x4002B8 CORE__DBN_CFG__PCIE_CORE_REG_axi_addr0 — holds the base address [31:8] of this region. Lower [5:0] is used for region size programmability
  fields as CORE__DBN_CFG__PCIE_CORE_REG_axi_addr0
0x4002BC CORE__DBN_CFG__PCIE_CORE_REG_axi_addr1 — holds the base address [63:32] of this region.
  fields as CORE__DBN_CFG__PCIE_CORE_REG_axi_addr1
0x4002C0 CORE__DBN_CFG__PCIE_CORE_REG_addr0 access per field — Provides bits 31:8 of the PCIe address and the number of AXI address bits passed through
  fields as CORE__DBN_CFG__PCIE_CORE_REG_addr0
0x4002C4 CORE__DBN_CFG__PCIE_CORE_REG_addr1 — Provides bits 63:32 of the PCIe address
  [31:0] DATA — Bits [63:32] of PCIe Address Register for region N
0x4002C8 CORE__DBN_CFG__PCIE_CORE_REG_desc0 — Provides bits 31:0 of the Outbound PCIe Descriptor
  fields as CORE__DBN_CFG__PCIE_CORE_REG_desc0
0x4002CC CORE__DBN_CFG__PCIE_CORE_REG_desc1 — Provides bits 63:32 of the PCIe Descriptor
  fields as CORE__DBN_CFG__PCIE_CORE_REG_desc1
0x4002D4 CORE__DBN_CFG__PCIE_CORE_REG_desc3 — Provides PASID Value and The present bit
  fields as CORE__DBN_CFG__PCIE_CORE_REG_desc3
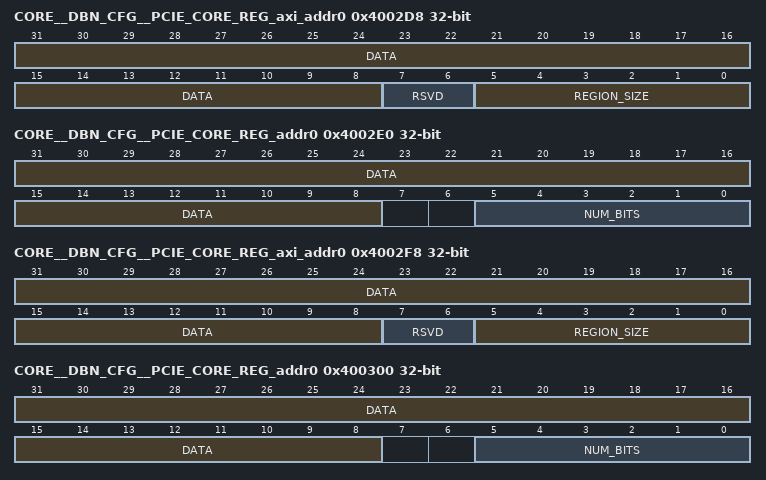
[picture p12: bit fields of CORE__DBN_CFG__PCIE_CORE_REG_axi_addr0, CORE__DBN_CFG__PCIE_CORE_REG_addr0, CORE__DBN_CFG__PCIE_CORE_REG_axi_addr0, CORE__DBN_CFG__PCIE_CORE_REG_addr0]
0x4002D8 CORE__DBN_CFG__PCIE_CORE_REG_axi_addr0 — holds the base address [31:8] of this region. Lower [5:0] is used for region size programmability
  fields as CORE__DBN_CFG__PCIE_CORE_REG_axi_addr0
0x4002DC CORE__DBN_CFG__PCIE_CORE_REG_axi_addr1 — holds the base address [63:32] of this region.
  fields as CORE__DBN_CFG__PCIE_CORE_REG_axi_addr1
0x4002E0 CORE__DBN_CFG__PCIE_CORE_REG_addr0 access per field — Provides bits 31:8 of the PCIe address and the number of AXI address bits passed through
  fields as CORE__DBN_CFG__PCIE_CORE_REG_addr0
0x4002E4 CORE__DBN_CFG__PCIE_CORE_REG_addr1 — Provides bits 63:32 of the PCIe address
  [31:0] DATA — Bits [63:32] of PCIe Address Register for region N
0x4002E8 CORE__DBN_CFG__PCIE_CORE_REG_desc0 — Provides bits 31:0 of the Outbound PCIe Descriptor
  fields as CORE__DBN_CFG__PCIE_CORE_REG_desc0
0x4002EC CORE__DBN_CFG__PCIE_CORE_REG_desc1 — Provides bits 63:32 of the PCIe Descriptor
  fields as CORE__DBN_CFG__PCIE_CORE_REG_desc1
0x4002F4 CORE__DBN_CFG__PCIE_CORE_REG_desc3 — Provides PASID Value and The present bit
  fields as CORE__DBN_CFG__PCIE_CORE_REG_desc3
0x4002F8 CORE__DBN_CFG__PCIE_CORE_REG_axi_addr0 — holds the base address [31:8] of this region. Lower [5:0] is used for region size programmability
  fields as CORE__DBN_CFG__PCIE_CORE_REG_axi_addr0
0x4002FC CORE__DBN_CFG__PCIE_CORE_REG_axi_addr1 — holds the base address [63:32] of this region.
  fields as CORE__DBN_CFG__PCIE_CORE_REG_axi_addr1
0x400300 CORE__DBN_CFG__PCIE_CORE_REG_addr0 access per field — Provides bits 31:8 of the PCIe address and the number of AXI address bits passed through
  fields as CORE__DBN_CFG__PCIE_CORE_REG_addr0
0x400304 CORE__DBN_CFG__PCIE_CORE_REG_addr1 — Provides bits 63:32 of the PCIe address
  [31:0] DATA — Bits [63:32] of PCIe Address Register for region N
0x400308 CORE__DBN_CFG__PCIE_CORE_REG_desc0 — Provides bits 31:0 of the Outbound PCIe Descriptor
  fields as CORE__DBN_CFG__PCIE_CORE_REG_desc0
0x40030C CORE__DBN_CFG__PCIE_CORE_REG_desc1 — Provides bits 63:32 of the PCIe Descriptor
  fields as CORE__DBN_CFG__PCIE_CORE_REG_desc1
0x400314 CORE__DBN_CFG__PCIE_CORE_REG_desc3 — Provides PASID Value and The present bit
  fields as CORE__DBN_CFG__PCIE_CORE_REG_desc3
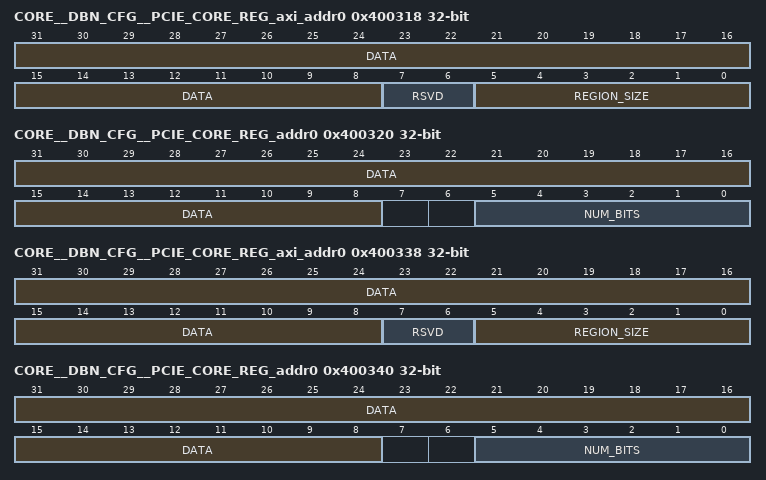
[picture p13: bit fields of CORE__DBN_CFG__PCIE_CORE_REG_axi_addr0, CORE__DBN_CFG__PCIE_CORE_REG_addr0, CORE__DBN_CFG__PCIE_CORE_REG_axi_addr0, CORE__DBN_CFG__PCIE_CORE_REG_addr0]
0x400318 CORE__DBN_CFG__PCIE_CORE_REG_axi_addr0 — holds the base address [31:8] of this region. Lower [5:0] is used for region size programmability
  fields as CORE__DBN_CFG__PCIE_CORE_REG_axi_addr0
0x40031C CORE__DBN_CFG__PCIE_CORE_REG_axi_addr1 — holds the base address [63:32] of this region.
  fields as CORE__DBN_CFG__PCIE_CORE_REG_axi_addr1
0x400320 CORE__DBN_CFG__PCIE_CORE_REG_addr0 access per field — Provides bits 31:8 of the PCIe address and the number of AXI address bits passed through
  fields as CORE__DBN_CFG__PCIE_CORE_REG_addr0
0x400324 CORE__DBN_CFG__PCIE_CORE_REG_addr1 — Provides bits 63:32 of the PCIe address
  [31:0] DATA — Bits [63:32] of PCIe Address Register for region N
0x400328 CORE__DBN_CFG__PCIE_CORE_REG_desc0 — Provides bits 31:0 of the Outbound PCIe Descriptor
  fields as CORE__DBN_CFG__PCIE_CORE_REG_desc0
0x40032C CORE__DBN_CFG__PCIE_CORE_REG_desc1 — Provides bits 63:32 of the PCIe Descriptor
  fields as CORE__DBN_CFG__PCIE_CORE_REG_desc1
0x400334 CORE__DBN_CFG__PCIE_CORE_REG_desc3 — Provides PASID Value and The present bit
  fields as CORE__DBN_CFG__PCIE_CORE_REG_desc3
0x400338 CORE__DBN_CFG__PCIE_CORE_REG_axi_addr0 — holds the base address [31:8] of this region. Lower [5:0] is used for region size programmability
  fields as CORE__DBN_CFG__PCIE_CORE_REG_axi_addr0
0x40033C CORE__DBN_CFG__PCIE_CORE_REG_axi_addr1 — holds the base address [63:32] of this region.
  fields as CORE__DBN_CFG__PCIE_CORE_REG_axi_addr1
0x400340 CORE__DBN_CFG__PCIE_CORE_REG_addr0 access per field — Provides bits 31:8 of the PCIe address and the number of AXI address bits passed through
  fields as CORE__DBN_CFG__PCIE_CORE_REG_addr0
0x400344 CORE__DBN_CFG__PCIE_CORE_REG_addr1 — Provides bits 63:32 of the PCIe address
  [31:0] DATA — Bits [63:32] of PCIe Address Register for region N
0x400348 CORE__DBN_CFG__PCIE_CORE_REG_desc0 — Provides bits 31:0 of the Outbound PCIe Descriptor
  fields as CORE__DBN_CFG__PCIE_CORE_REG_desc0
0x40034C CORE__DBN_CFG__PCIE_CORE_REG_desc1 — Provides bits 63:32 of the PCIe Descriptor
  fields as CORE__DBN_CFG__PCIE_CORE_REG_desc1
0x400354 CORE__DBN_CFG__PCIE_CORE_REG_desc3 — Provides PASID Value and The present bit
  fields as CORE__DBN_CFG__PCIE_CORE_REG_desc3
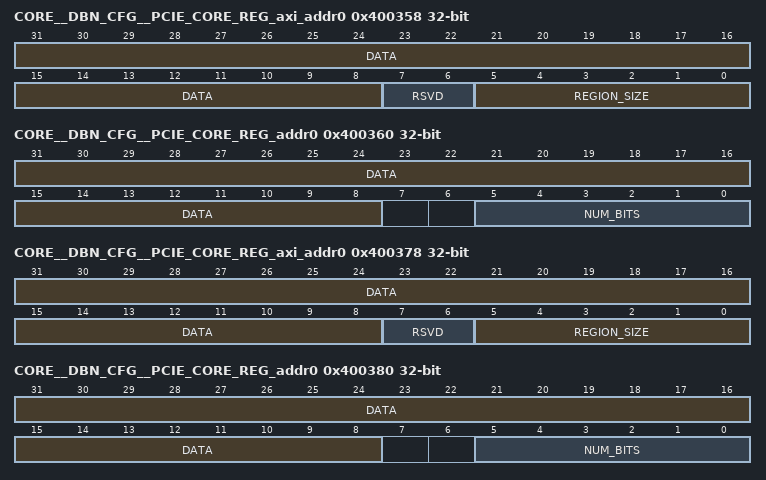
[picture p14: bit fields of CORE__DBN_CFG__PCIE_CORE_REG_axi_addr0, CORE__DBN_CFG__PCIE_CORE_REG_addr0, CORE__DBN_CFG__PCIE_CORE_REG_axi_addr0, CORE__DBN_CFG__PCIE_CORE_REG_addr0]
0x400358 CORE__DBN_CFG__PCIE_CORE_REG_axi_addr0 — holds the base address [31:8] of this region. Lower [5:0] is used for region size programmability
  fields as CORE__DBN_CFG__PCIE_CORE_REG_axi_addr0
0x40035C CORE__DBN_CFG__PCIE_CORE_REG_axi_addr1 — holds the base address [63:32] of this region.
  fields as CORE__DBN_CFG__PCIE_CORE_REG_axi_addr1
0x400360 CORE__DBN_CFG__PCIE_CORE_REG_addr0 access per field — Provides bits 31:8 of the PCIe address and the number of AXI address bits passed through
  fields as CORE__DBN_CFG__PCIE_CORE_REG_addr0
0x400364 CORE__DBN_CFG__PCIE_CORE_REG_addr1 — Provides bits 63:32 of the PCIe address
  [31:0] DATA — Bits [63:32] of PCIe Address Register for region N
0x400368 CORE__DBN_CFG__PCIE_CORE_REG_desc0 — Provides bits 31:0 of the Outbound PCIe Descriptor
  fields as CORE__DBN_CFG__PCIE_CORE_REG_desc0
0x40036C CORE__DBN_CFG__PCIE_CORE_REG_desc1 — Provides bits 63:32 of the PCIe Descriptor
  fields as CORE__DBN_CFG__PCIE_CORE_REG_desc1
0x400374 CORE__DBN_CFG__PCIE_CORE_REG_desc3 — Provides PASID Value and The present bit
  fields as CORE__DBN_CFG__PCIE_CORE_REG_desc3
0x400378 CORE__DBN_CFG__PCIE_CORE_REG_axi_addr0 — holds the base address [31:8] of this region. Lower [5:0] is used for region size programmability
  fields as CORE__DBN_CFG__PCIE_CORE_REG_axi_addr0
0x40037C CORE__DBN_CFG__PCIE_CORE_REG_axi_addr1 — holds the base address [63:32] of this region.
  fields as CORE__DBN_CFG__PCIE_CORE_REG_axi_addr1
0x400380 CORE__DBN_CFG__PCIE_CORE_REG_addr0 access per field — Provides bits 31:8 of the PCIe address and the number of AXI address bits passed through
  fields as CORE__DBN_CFG__PCIE_CORE_REG_addr0
0x400384 CORE__DBN_CFG__PCIE_CORE_REG_addr1 — Provides bits 63:32 of the PCIe address
  [31:0] DATA — Bits [63:32] of PCIe Address Register for region N
0x400388 CORE__DBN_CFG__PCIE_CORE_REG_desc0 — Provides bits 31:0 of the Outbound PCIe Descriptor
  fields as CORE__DBN_CFG__PCIE_CORE_REG_desc0
0x40038C CORE__DBN_CFG__PCIE_CORE_REG_desc1 — Provides bits 63:32 of the PCIe Descriptor
  fields as CORE__DBN_CFG__PCIE_CORE_REG_desc1
0x400394 CORE__DBN_CFG__PCIE_CORE_REG_desc3 — Provides PASID Value and The present bit
  fields as CORE__DBN_CFG__PCIE_CORE_REG_desc3
0x400398 CORE__DBN_CFG__PCIE_CORE_REG_axi_addr0 — holds the base address [31:8] of this region. Lower [5:0] is used for region size programmability
  fields as CORE__DBN_CFG__PCIE_CORE_REG_axi_addr0
0x40039C CORE__DBN_CFG__PCIE_CORE_REG_axi_addr1 — holds the base address [63:32] of this region.
  fields as CORE__DBN_CFG__PCIE_CORE_REG_axi_addr1
0x4003A0 CORE__DBN_CFG__PCIE_CORE_REG_addr0 access per field — Provides bits 31:8 of the PCIe address and the number of AXI address bits passed through
  fields as CORE__DBN_CFG__PCIE_CORE_REG_addr0
0x4003A4 CORE__DBN_CFG__PCIE_CORE_REG_addr1 — Provides bits 63:32 of the PCIe address
  [31:0] DATA — Bits [63:32] of PCIe Address Register for region N
0x4003A8 CORE__DBN_CFG__PCIE_CORE_REG_desc0 — Provides bits 31:0 of the Outbound PCIe Descriptor
  fields as CORE__DBN_CFG__PCIE_CORE_REG_desc0
0x4003AC CORE__DBN_CFG__PCIE_CORE_REG_desc1 — Provides bits 63:32 of the PCIe Descriptor
  fields as CORE__DBN_CFG__PCIE_CORE_REG_desc1
0x4003B4 CORE__DBN_CFG__PCIE_CORE_REG_desc3 — Provides PASID Value and The present bit
  fields as CORE__DBN_CFG__PCIE_CORE_REG_desc3
0x4003B8 CORE__DBN_CFG__PCIE_CORE_REG_axi_addr0 — holds the base address [31:8] of this region. Lower [5:0] is used for region size programmability
  fields as CORE__DBN_CFG__PCIE_CORE_REG_axi_addr0
0x4003BC CORE__DBN_CFG__PCIE_CORE_REG_axi_addr1 — holds the base address [63:32] of this region.
  fields as CORE__DBN_CFG__PCIE_CORE_REG_axi_addr1
0x4003C0 CORE__DBN_CFG__PCIE_CORE_REG_addr0 access per field — Provides bits 31:8 of the PCIe address and the number of AXI address bits passed through
  fields as CORE__DBN_CFG__PCIE_CORE_REG_addr0
0x4003C4 CORE__DBN_CFG__PCIE_CORE_REG_addr1 — Provides bits 63:32 of the PCIe address
  [31:0] DATA — Bits [63:32] of PCIe Address Register for region N
0x4003C8 CORE__DBN_CFG__PCIE_CORE_REG_desc0 — Provides bits 31:0 of the Outbound PCIe Descriptor
  fields as CORE__DBN_CFG__PCIE_CORE_REG_desc0
0x4003CC CORE__DBN_CFG__PCIE_CORE_REG_desc1 — Provides bits 63:32 of the PCIe Descriptor
  fields as CORE__DBN_CFG__PCIE_CORE_REG_desc1
0x4003D4 CORE__DBN_CFG__PCIE_CORE_REG_desc3 — Provides PASID Value and The present bit
  fields as CORE__DBN_CFG__PCIE_CORE_REG_desc3
0x4003D8 CORE__DBN_CFG__PCIE_CORE_REG_axi_addr0 — holds the base address [31:8] of this region. Lower [5:0] is used for region size programmability
  fields as CORE__DBN_CFG__PCIE_CORE_REG_axi_addr0
0x4003DC CORE__DBN_CFG__PCIE_CORE_REG_axi_addr1 — holds the base address [63:32] of this region.
  fields as CORE__DBN_CFG__PCIE_CORE_REG_axi_addr1
0x4003E0 CORE__DBN_CFG__PCIE_CORE_REG_addr0 access per field — Provides bits 31:8 of the PCIe address and the number of AXI address bits passed through
  fields as CORE__DBN_CFG__PCIE_CORE_REG_addr0
0x4003E4 CORE__DBN_CFG__PCIE_CORE_REG_addr1 — Provides bits 63:32 of the PCIe address
  [31:0] DATA — Bits [63:32] of PCIe Address Register for region N
0x4003E8 CORE__DBN_CFG__PCIE_CORE_REG_desc0 — Provides bits 31:0 of the Outbound PCIe Descriptor
  fields as CORE__DBN_CFG__PCIE_CORE_REG_desc0
0x4003EC CORE__DBN_CFG__PCIE_CORE_REG_desc1 — Provides bits 63:32 of the PCIe Descriptor
  fields as CORE__DBN_CFG__PCIE_CORE_REG_desc1
0x4003F4 CORE__DBN_CFG__PCIE_CORE_REG_desc3 — Provides PASID Value and The present bit
  fields as CORE__DBN_CFG__PCIE_CORE_REG_desc3
0x4003F8 CORE__DBN_CFG__PCIE_CORE_REG_axi_addr0 — holds the base address [31:8] of this region. Lower [5:0] is used for region size programmability
  fields as CORE__DBN_CFG__PCIE_CORE_REG_axi_addr0
0x4003FC CORE__DBN_CFG__PCIE_CORE_REG_axi_addr1 — holds the base address [63:32] of this region.
  fields as CORE__DBN_CFG__PCIE_CORE_REG_axi_addr1
0x400800 CORE__DBN_CFG__PCIE_CORE_REG_addr0 access per field — Provides bits 31:8 of the AXI Address and the number of PCIE address bits passed through
  [31:8] DATA rw — Bits [31:8] of AXI Address Register for BAR N
  [5:0] NUM_BITS rw — The value programmed in this register +1 bits are passed through from PCIe to AXI
0x400804 CORE__DBN_CFG__PCIE_CORE_REG_addr1 — Provides bits 63:32 of the AXI Address
  [31:0] DATA — Bits [63:32] of AXI Address Register for BAR N
0x400808 CORE__DBN_CFG__PCIE_CORE_REG_addr0 access per field — Provides bits 31:8 of the AXI Address and the number of PCIE address bits passed through
  [31:8] DATA rw — Bits [31:8] of AXI Address Register for BAR N
  [5:0] NUM_BITS rw — The value programmed in this register +1 bits are passed through from PCIe to AXI
0x40080C CORE__DBN_CFG__PCIE_CORE_REG_addr1 — Provides bits 63:32 of the AXI Address
  [31:0] DATA — Bits [63:32] of AXI Address Register for BAR N
0x400810 CORE__DBN_CFG__PCIE_CORE_REG_addr0 access per field — Provides bits 31:8 of the AXI Address and the number of PCIE address bits passed through
  [31:8] DATA rw — Bits [31:8] of AXI Address Register for BAR N
  [5:0] NUM_BITS rw — The value programmed in this register +1 bits are passed through from PCIe to AXI
0x400814 CORE__DBN_CFG__PCIE_CORE_REG_addr1 — Provides bits 63:32 of the AXI Address
  [31:0] DATA — Bits [63:32] of AXI Address Register for BAR N
0x400820 CORE__DBN_CFG__PCIE_CORE_REG_c0 reset 0x1010
  [19:12] HEADER — This is the threshold value of the header credits required which is used to flag credit availability in AXI wrapper
  [11:0] DATA — This is the threshold value of the payload credits required which is used to flag credit availability in AXI wrapper
0x400824 CORE__DBN_CFG__PCIE_CORE_REG_L0
  [0] CLEAR_LINK_DOWN_BIT_TO_PROCEED — This bit will be set when link down reset comes. client should clear this bit before issueing new traffic to the core
